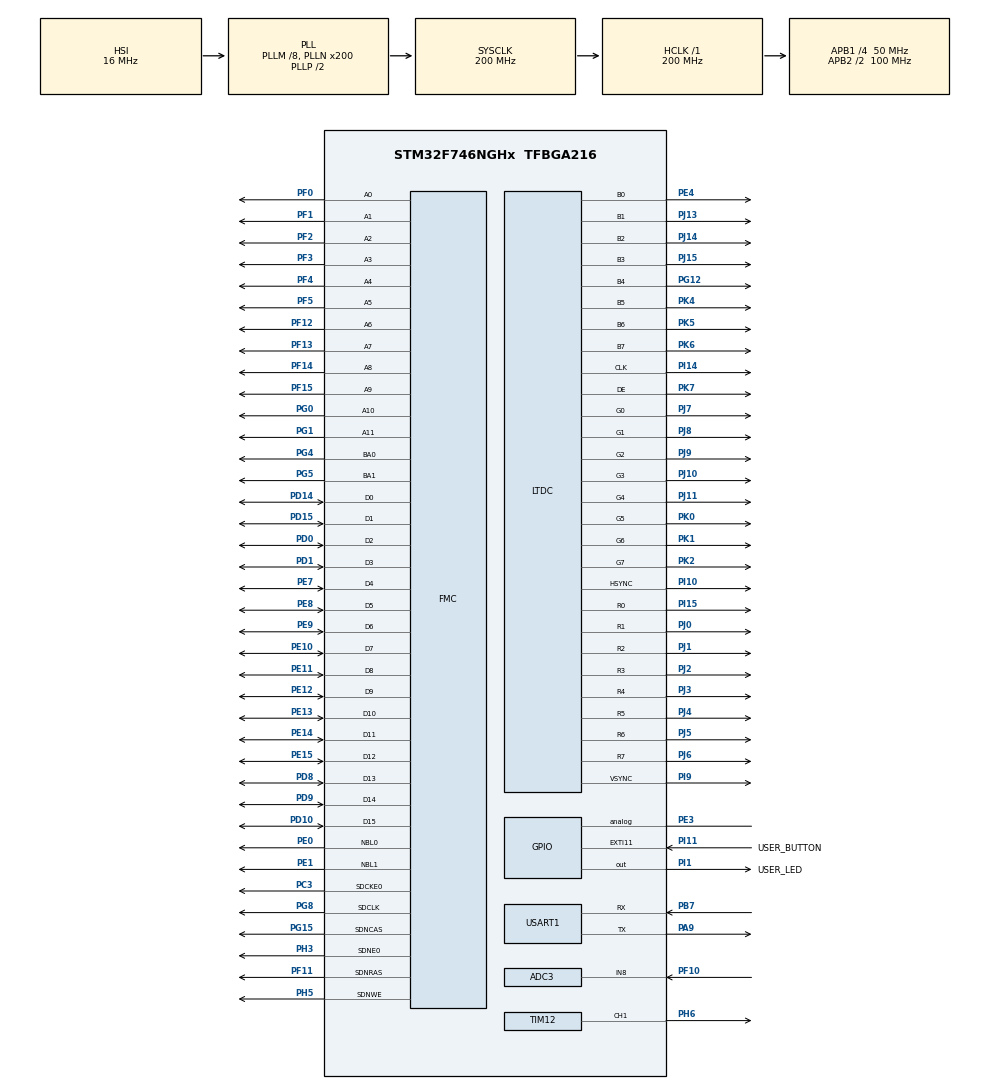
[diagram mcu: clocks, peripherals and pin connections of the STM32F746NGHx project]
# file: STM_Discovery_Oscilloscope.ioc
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ADC1.Channel-0\#ChannelRegularConversion=ADC_CHANNEL_VREFINT
ADC1.NbrOfConversionFlag=1
ADC1.Rank-0\#ChannelRegularConversion=1
ADC1.SamplingTime-0\#ChannelRegularConversion=ADC_SAMPLETIME_3CYCLES
ADC1.master=1
ADC3.Channel-0\#ChannelRegularConversion=ADC_CHANNEL_8
ADC3.ContinuousConvMode=ENABLE
ADC3.DMAContinuousRequests=ENABLE
ADC3.NbrOfConversionFlag=1
ADC3.Rank-0\#ChannelRegularConversion=1
ADC3.SamplingTime-0\#ChannelRegularConversion=ADC_SAMPLETIME_480CYCLES
ADC3.ScanConvMode=ADC_SCAN_ENABLE
CORTEX_M7.default_mode_Activation=1
DMA2D.ColorMode=DMA2D_OUTPUT_RGB888
Dma.ADC3.0.Direction=DMA_PERIPH_TO_MEMORY
Dma.ADC3.0.FIFOMode=DMA_FIFOMODE_DISABLE
Dma.ADC3.0.Instance=DMA2_Stream0
Dma.ADC3.0.MemDataAlignment=DMA_MDATAALIGN_HALFWORD
Dma.ADC3.0.MemInc=DMA_MINC_ENABLE
Dma.ADC3.0.Mode=DMA_CIRCULAR
Dma.ADC3.0.PeriphDataAlignment=DMA_PDATAALIGN_HALFWORD
Dma.ADC3.0.PeriphInc=DMA_PINC_DISABLE
Dma.ADC3.0.Priority=DMA_PRIORITY_LOW
Dma.Request0=ADC3
LTDC.ActiveH=272
LTDC.ActiveW=480
LTDC.Alpha0_L0=0
LTDC.Alpha0_L1=100
LTDC.Alpha_L0=255
LTDC.Blue=0
LTDC.Blue_L0=0
LTDC.Blue_L1=100
LTDC.DEPolarity=LTDC_DEPOLARITY_AH
LTDC.Green=0
LTDC.HBP=43
LTDC.HFP=8
LTDC.HSPolarity=LTDC_HSPOLARITY_AL
LTDC.HSync=10
LTDC.ImageHeight_L0=272
LTDC.ImageHeight_L1=272
LTDC.ImageWidth_L0=480
LTDC.ImageWidth_L1=480
LTDC.Layers=0
LTDC.PixelFormat_L0=LTDC_PIXEL_FORMAT_RGB888
LTDC.Red=0
LTDC.VBP=12
LTDC.VFP=4
LTDC.VSPolarity=LTDC_VSPOLARITY_AL
LTDC.VSync=10
LTDC.WindowX1_L0=480
LTDC.WindowX1_L1=480
LTDC.WindowY1_L0=272
LTDC.WindowY1_L1=272
Mcu.Family=STM32F7
Mcu.Name=STM32F746NGHx
Mcu.Package=TFBGA216
NVIC.ADC_IRQn=true\:2\:0\:true\:false\:true\:true\:true\:true
NVIC.DMA2D_IRQn=true\:2\:0\:true\:false\:true\:true\:true\:true
NVIC.DMA2_Stream0_IRQn=true\:2\:0\:true\:false\:true\:false\:true\:true
NVIC.EXTI15_10_IRQn=true\:6\:0\:true\:false\:true\:true\:true\:true
NVIC.FMC_IRQn=true\:4\:0\:true\:false\:true\:true\:true\:true
NVIC.LTDC_IRQn=true\:0\:0\:false\:false\:true\:true\:true\:true
NVIC.PriorityGroup=NVIC_PRIORITYGROUP_4
PA13.Mode=Serial_Wire
PA13.Signal=SYS_JTMS-SWDIO
PA14.Mode=Serial_Wire
PA14.Signal=SYS_JTCK-SWCLK
PA9.Mode=Asynchronous
PA9.Signal=USART1_TX
PB7.Mode=Asynchronous
PB7.Signal=USART1_RX
PC3.Mode=SdramChipSelect1_1
PC3.Signal=FMC_SDCKE0
PD0.Signal=FMC_D2_DA2
PD1.Signal=FMC_D3_DA3
PD10.Signal=FMC_D15_DA15
PD14.Signal=FMC_D0_DA0
PD15.Signal=FMC_D1_DA1
PD8.Signal=FMC_D13_DA13
PD9.Signal=FMC_D14_DA14
PE0.Signal=FMC_NBL0
PE1.Signal=FMC_NBL1
PE10.Signal=FMC_D7_DA7
PE11.Signal=FMC_D8_DA8
PE12.Signal=FMC_D9_DA9
PE13.Signal=FMC_D10_DA10
PE14.Signal=FMC_D11_DA11
PE15.Signal=FMC_D12_DA12
PE3.Signal=GPIO_Analog
PE4.Mode=RGB888
PE4.Signal=LTDC_B0
PE7.Signal=FMC_D4_DA4
PE8.Signal=FMC_D5_DA5
PE9.Signal=FMC_D6_DA6
PF0.Signal=FMC_A0
PF1.Signal=FMC_A1
PF10.Mode=IN8
PF10.Signal=ADC3_IN8
PF11.Signal=FMC_SDNRAS
PF12.Signal=FMC_A6
PF13.Signal=FMC_A7
PF14.Signal=FMC_A8
PF15.Signal=FMC_A9
PF2.Signal=FMC_A2
PF3.Signal=FMC_A3
PF4.Signal=FMC_A4
PF5.Signal=FMC_A5
PG0.Signal=FMC_A10
PG1.Signal=FMC_A11
PG12.Mode=RGB888
PG12.Signal=LTDC_B4
PG15.Signal=FMC_SDNCAS
PG4.Signal=FMC_A14_BA0
PG5.Signal=FMC_A15_BA1
PG8.Signal=FMC_SDCLK
PH0/OSC_IN.Mode=HSE-External-Clock-Source
PH0/OSC_IN.Signal=RCC_OSC_IN
PH1/OSC_OUT.Mode=HSE-External-Clock-Source
PH1/OSC_OUT.Signal=RCC_OSC_OUT
PH3.Mode=SdramChipSelect1_1
PH3.Signal=FMC_SDNE0
PH5.Signal=FMC_SDNWE
PH6.Signal=S_TIM12_CH1
PI1.GPIO_Label=USER_LED
PI1.Signal=GPIO_Output
PI10.Mode=RGB888
PI10.Signal=LTDC_HSYNC
PI11.GPIO_Label=USER_BUTTON
PI11.Signal=GPXTI11
PI14.Mode=RGB888
PI14.Signal=LTDC_CLK
PI15.Mode=RGB888
PI15.Signal=LTDC_R0
PI9.Mode=RGB888
PI9.Signal=LTDC_VSYNC
PJ0.Mode=RGB888
PJ0.Signal=LTDC_R1
PJ1.Mode=RGB888
PJ1.Signal=LTDC_R2
PJ10.Mode=RGB888
PJ10.Signal=LTDC_G3
PJ11.Mode=RGB888
PJ11.Signal=LTDC_G4
PJ13.Mode=RGB888
PJ13.Signal=LTDC_B1
PJ14.Mode=RGB888
PJ14.Signal=LTDC_B2
PJ15.Mode=RGB888
PJ15.Signal=LTDC_B3
PJ2.Mode=RGB888
PJ2.Signal=LTDC_R3
PJ3.Mode=RGB888
PJ3.Signal=LTDC_R4
PJ4.Mode=RGB888
PJ4.Signal=LTDC_R5
PJ5.Mode=RGB888
PJ5.Signal=LTDC_R6
PJ6.Mode=RGB888
PJ6.Signal=LTDC_R7
PJ7.Mode=RGB888
PJ7.Signal=LTDC_G0
PJ8.Mode=RGB888
PJ8.Signal=LTDC_G1
PJ9.Mode=RGB888
PJ9.Signal=LTDC_G2
PK0.Mode=RGB888
PK0.Signal=LTDC_G5
PK1.Mode=RGB888
PK1.Signal=LTDC_G6
PK2.Mode=RGB888
PK2.Signal=LTDC_G7
PK4.Mode=RGB888
PK4.Signal=LTDC_B5
PK5.Mode=RGB888
PK5.Signal=LTDC_B6
PK6.Mode=RGB888
PK6.Signal=LTDC_B7
PK7.Mode=RGB888
PK7.Signal=LTDC_DE
ProjectManager.HeapSize=0x200
ProjectManager.StackSize=0x4000
ProjectManager.TargetToolchain=STM32CubeIDE
RCC.AHBFreq_Value=200000000
RCC.APB1CLKDivider=RCC_HCLK_DIV4
RCC.APB1Freq_Value=50000000
RCC.APB1TimFreq_Value=100000000
RCC.APB2CLKDivider=RCC_HCLK_DIV2
RCC.APB2Freq_Value=100000000
RCC.APB2TimFreq_Value=200000000
RCC.CortexFreq_Value=200000000
RCC.HCLKFreq_Value=200000000
RCC.HSE_VALUE=25000000
RCC.HSI_VALUE=16000000
RCC.LSE_VALUE=32768
RCC.PLLM=8
RCC.PLLN=200
RCC.PLLSAIN=50
RCC.SYSCLKFreq_VALUE=200000000
RCC.SYSCLKSource=RCC_SYSCLKSOURCE_PLLCLK
RCC.USART1CLockSelection=RCC_USART1CLKSOURCE_HSI
RCC.USBFreq_Value=200000000
RCC.VCOOutputFreq_Value=400000000
SH.FMC_A0.0=FMC_A0,12b-sda1
SH.FMC_A1.0=FMC_A1,12b-sda1
SH.FMC_A10.0=FMC_A10,12b-sda1
SH.FMC_A11.0=FMC_A11,12b-sda1
SH.FMC_A14_BA0.0=FMC_BA0,FourSdramBanks1
SH.FMC_A15_BA1.0=FMC_BA1,FourSdramBanks1
SH.FMC_A2.0=FMC_A2,12b-sda1
SH.FMC_A3.0=FMC_A3,12b-sda1
SH.FMC_A4.0=FMC_A4,12b-sda1
SH.FMC_A5.0=FMC_A5,12b-sda1
SH.FMC_A6.0=FMC_A6,12b-sda1
SH.FMC_A7.0=FMC_A7,12b-sda1
SH.FMC_A8.0=FMC_A8,12b-sda1
SH.FMC_A9.0=FMC_A9,12b-sda1
SH.FMC_D0_DA0.0=FMC_D0,sd-16b-d1
SH.FMC_D10_DA10.0=FMC_D10,sd-16b-d1
SH.FMC_D11_DA11.0=FMC_D11,sd-16b-d1
SH.FMC_D12_DA12.0=FMC_D12,sd-16b-d1
SH.FMC_D13_DA13.0=FMC_D13,sd-16b-d1
SH.FMC_D14_DA14.0=FMC_D14,sd-16b-d1
SH.FMC_D15_DA15.0=FMC_D15,sd-16b-d1
SH.FMC_D1_DA1.0=FMC_D1,sd-16b-d1
SH.FMC_D2_DA2.0=FMC_D2,sd-16b-d1
SH.FMC_D3_DA3.0=FMC_D3,sd-16b-d1
SH.FMC_D4_DA4.0=FMC_D4,sd-16b-d1
SH.FMC_D5_DA5.0=FMC_D5,sd-16b-d1
SH.FMC_D6_DA6.0=FMC_D6,sd-16b-d1
SH.FMC_D7_DA7.0=FMC_D7,sd-16b-d1
SH.FMC_D8_DA8.0=FMC_D8,sd-16b-d1
SH.FMC_D9_DA9.0=FMC_D9,sd-16b-d1
SH.FMC_NBL0.0=FMC_NBL0,Sd2ByteEnable1
SH.FMC_NBL1.0=FMC_NBL1,Sd2ByteEnable1
SH.FMC_SDCLK.0=FMC_SDCLK,12b-sda1
SH.FMC_SDNCAS.0=FMC_SDNCAS,12b-sda1
SH.FMC_SDNRAS.0=FMC_SDNRAS,12b-sda1
SH.FMC_SDNWE.0=FMC_SDNWE,12b-sda1
SH.S_TIM12_CH1.0=TIM12_CH1,PWM Generation1 CH1
TIM12.Channel-PWM\ Generation1\ CH1=TIM_CHANNEL_1
TIM12.Period=1000
TIM12.Prescaler=9999
USART1.VirtualMode-Asynchronous=VM_ASYNC
VP_ADC1_Vref_Input.Mode=IN-Vrefint
VP_DMA2D_VS_DMA2D.Mode=DMA2D_Activate
VP_TIM12_VS_ClockSourceINT.Mode=Internal
VP_TIM7_VS_ClockSourceINT.Mode=Enable_Timer
board=custom

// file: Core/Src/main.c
/* USER CODE BEGIN Header */
/**
  ******************************************************************************
  * @file           : main.c
  * @brief          : Main program body
  ******************************************************************************
  * @attention
  *
  * Copyright (c) 2025 STMicroelectronics.
  * All rights reserved.
  *
  * This software is licensed under terms that can be found in the LICENSE file
  * in the root directory of this software component.
  * If no LICENSE file comes with this software, it is provided AS-IS.
  *
  ******************************************************************************
  */
/* USER CODE END Header */
#include "main.h"
#include "adc.h"
#include "dma.h"
#include "dma2d.h"
#include "ltdc.h"
#include "tim.h"
#include "usart.h"
#include "gpio.h"
#include "fmc.h"

void SystemClock_Config(void);
static void MPU_Config(void);
/* USER CODE BEGIN PFP */
void CPU_CACHE_Enable(void);
/* USER CODE END PFP */

/* USER CODE BEGIN 0 */
int __io_putchar(int ch)
{
    HAL_UART_Transmit(&huart1, (uint8_t*)&ch, 1, HAL_MAX_DELAY);
    return 1;
}

void CPU_CACHE_Enable(void)
{
  SCB_EnableICache();
  SCB_EnableDCache();
}

/* USER CODE END 0 */

int main(void)
{

  /* MPU Configuration--------------------------------------------------------*/
  MPU_Config();

  /* MCU Configuration--------------------------------------------------------*/

  /* Reset of all peripherals, Initializes the Flash interface and the Systick. */
  HAL_Init();

  /* USER CODE BEGIN Init */
  CPU_CACHE_Enable();
  /* USER CODE END Init */

  /* Configure the system clock */
  SystemClock_Config();

  /* Initialize all configured peripherals */
  MX_GPIO_Init();
  MX_DMA_Init();
  MX_USART1_UART_Init();
  MX_LTDC_Init();
  MX_TIM7_Init();
  MX_DMA2D_Init();
  MX_FMC_Init();
  BSP_SDRAM_Init();
  MX_ADC1_Init();
  MX_ADC3_Init();
  MX_TIM12_Init();
  /* USER CODE BEGIN 2 */
  display_init();

  // !!! @ATTENTION SDRAM AND LTDC HAVE TO BE INITIALIZED IN THIS WAY:!!! -> (BSP_SDRAM_Init() before MX_ADC1/MX_ADC3 _Init)
  //BSP_SDRAM_Init();

	//uint32_t ADC_buffer = 0;

  /* USER CODE END 2 */

  /* Infinite loop */
  /* USER CODE BEGIN WHILE */
	while (1)
	{
		//	  printf("...***...\n\r");
		//	  HAL_GPIO_TogglePin(USER_LED_GPIO_Port, USER_LED_Pin);
		//	  HAL_Delay(900);

		//ADC_getCurrentValue(&ADC_buffer); //ADC Circular mode and DMA test
		//printf("ADC value: %ld\n\r", ADC_buffer);
		//HAL_Delay(200);

		HAL_Delay(100);
		lv_task_handler();

    /* USER CODE END WHILE */

	}
}

void SystemClock_Config(void)
{
  RCC_OscInitTypeDef RCC_OscInitStruct = {0};
  RCC_ClkInitTypeDef RCC_ClkInitStruct = {0};

  /** Configure the main internal regulator output voltage
  */
  __HAL_RCC_PWR_CLK_ENABLE();
  __HAL_PWR_VOLTAGESCALING_CONFIG(PWR_REGULATOR_VOLTAGE_SCALE1);

  /** Initializes the RCC Oscillators according to the specified parameters
  * in the RCC_OscInitTypeDef structure.
  */
  RCC_OscInitStruct.OscillatorType = RCC_OSCILLATORTYPE_HSI;
  RCC_OscInitStruct.HSIState = RCC_HSI_ON;
  RCC_OscInitStruct.HSICalibrationValue = RCC_HSICALIBRATION_DEFAULT;
  RCC_OscInitStruct.PLL.PLLState = RCC_PLL_ON;
  RCC_OscInitStruct.PLL.PLLSource = RCC_PLLSOURCE_HSI;
  RCC_OscInitStruct.PLL.PLLM = 8;
  RCC_OscInitStruct.PLL.PLLN = 200;
  RCC_OscInitStruct.PLL.PLLP = RCC_PLLP_DIV2;
  RCC_OscInitStruct.PLL.PLLQ = 2;
  if (HAL_RCC_OscConfig(&RCC_OscInitStruct) != HAL_OK)
  {
    Error_Handler();
  }

  /** Activate the Over-Drive mode
  */
  if (HAL_PWREx_EnableOverDrive() != HAL_OK)
  {
    Error_Handler();
  }

  /** Initializes the CPU, AHB and APB buses clocks
  */
  RCC_ClkInitStruct.ClockType = RCC_CLOCKTYPE_HCLK|RCC_CLOCKTYPE_SYSCLK
                              |RCC_CLOCKTYPE_PCLK1|RCC_CLOCKTYPE_PCLK2;
  RCC_ClkInitStruct.SYSCLKSource = RCC_SYSCLKSOURCE_PLLCLK;
  RCC_ClkInitStruct.AHBCLKDivider = RCC_SYSCLK_DIV1;
  RCC_ClkInitStruct.APB1CLKDivider = RCC_HCLK_DIV4;
  RCC_ClkInitStruct.APB2CLKDivider = RCC_HCLK_DIV2;

  if (HAL_RCC_ClockConfig(&RCC_ClkInitStruct, FLASH_LATENCY_6) != HAL_OK)
  {
    Error_Handler();
  }
}

/* USER CODE BEGIN 4 */
static void MPU_Config(void)
{
  MPU_Region_InitTypeDef MPU_InitStruct;

  /* Disable the MPU */
  HAL_MPU_Disable();

  /* Configure the MPU as Strongly ordered for not defined regions */
  MPU_InitStruct.Enable = MPU_REGION_ENABLE;
  MPU_InitStruct.BaseAddress = 0x00;
  MPU_InitStruct.Size = MPU_REGION_SIZE_4GB;
  MPU_InitStruct.AccessPermission = MPU_REGION_NO_ACCESS;
  MPU_InitStruct.IsBufferable = MPU_ACCESS_NOT_BUFFERABLE;
  MPU_InitStruct.IsCacheable = MPU_ACCESS_NOT_CACHEABLE;
  MPU_InitStruct.IsShareable = MPU_ACCESS_SHAREABLE;
  MPU_InitStruct.Number = MPU_REGION_NUMBER0;
  MPU_InitStruct.TypeExtField = MPU_TEX_LEVEL0;
  MPU_InitStruct.SubRegionDisable = 0x87;
  MPU_InitStruct.DisableExec = MPU_INSTRUCTION_ACCESS_DISABLE;

  HAL_MPU_ConfigRegion(&MPU_InitStruct);

  /* Configure the MPU QSPI flash */
  MPU_InitStruct.Enable = MPU_REGION_ENABLE;
  MPU_InitStruct.BaseAddress = 0xC0000000;
  MPU_InitStruct.Size = MPU_REGION_SIZE_16MB;
  MPU_InitStruct.AccessPermission = MPU_REGION_FULL_ACCESS;
  MPU_InitStruct.IsBufferable = MPU_ACCESS_NOT_BUFFERABLE;
  MPU_InitStruct.IsCacheable = MPU_ACCESS_CACHEABLE;
  MPU_InitStruct.IsShareable = MPU_ACCESS_NOT_SHAREABLE;
  MPU_InitStruct.Number = MPU_REGION_NUMBER1;
  MPU_InitStruct.TypeExtField = MPU_TEX_LEVEL0;
  MPU_InitStruct.SubRegionDisable = 0x0;
  MPU_InitStruct.DisableExec = MPU_INSTRUCTION_ACCESS_ENABLE;

  HAL_MPU_ConfigRegion(&MPU_InitStruct);

  /* Configure the MPU attributes QSPI control registers */
  MPU_InitStruct.Enable = MPU_REGION_ENABLE;
  MPU_InitStruct.BaseAddress = 0xA0000000;
  MPU_InitStruct.Size = MPU_REGION_SIZE_8KB;
  MPU_InitStruct.AccessPermission = MPU_REGION_FULL_ACCESS;
  MPU_InitStruct.IsBufferable = MPU_ACCESS_BUFFERABLE;
  MPU_InitStruct.IsCacheable = MPU_ACCESS_NOT_CACHEABLE;
  MPU_InitStruct.IsShareable = MPU_ACCESS_SHAREABLE;
  MPU_InitStruct.Number = MPU_REGION_NUMBER2;
  MPU_InitStruct.TypeExtField = MPU_TEX_LEVEL0;
  MPU_InitStruct.SubRegionDisable = 0x0;
  MPU_InitStruct.DisableExec = MPU_INSTRUCTION_ACCESS_DISABLE;

  HAL_MPU_ConfigRegion(&MPU_InitStruct);

  /* Enable the MPU */
  HAL_MPU_Enable(MPU_PRIVILEGED_DEFAULT);
}
/* USER CODE END 4 */

 /* MPU Configuration */

void Error_Handler(void)
{
  __disable_irq();
  while (1)
  {
  }
}
